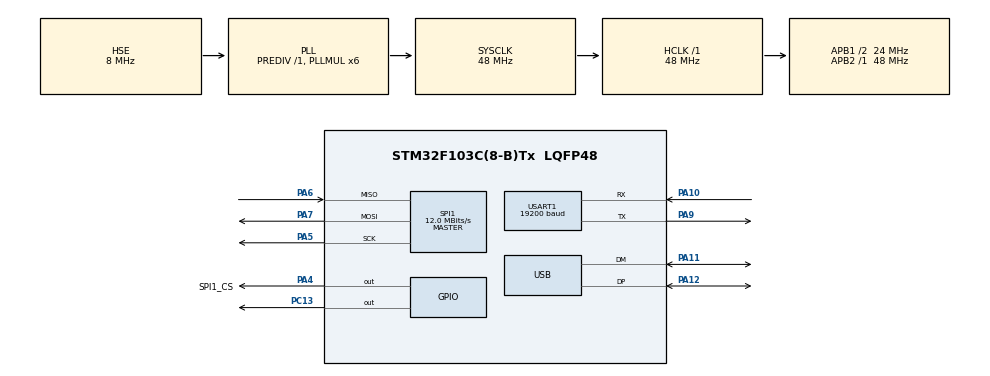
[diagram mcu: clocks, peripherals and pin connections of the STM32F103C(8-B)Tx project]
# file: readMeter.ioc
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Mcu.Family=STM32F1
Mcu.Name=STM32F103C(8-B)Tx
Mcu.Package=LQFP48
NVIC.PriorityGroup=NVIC_PRIORITYGROUP_4
NVIC.RTC_IRQn=true\:0\:0\:false\:false\:true\:true
NVIC.USART1_IRQn=true\:0\:0\:false\:true\:true\:1\:true
NVIC.USB_LP_CAN1_RX0_IRQn=true\:0\:0\:false\:false\:true\:false
PA10.Mode=Asynchronous
PA10.Signal=USART1_RX
PA11.Mode=Device
PA11.Signal=USB_DM
PA12.Mode=Device
PA12.Signal=USB_DP
PA4.GPIO_Label=SPI1_CS
PA4.Signal=GPIO_Output
PA5.Mode=Full_Duplex_Master
PA5.Signal=SPI1_SCK
PA6.Mode=Full_Duplex_Master
PA6.Signal=SPI1_MISO
PA7.Mode=Full_Duplex_Master
PA7.Signal=SPI1_MOSI
PA9.Mode=Asynchronous
PA9.Signal=USART1_TX
PC13-TAMPER-RTC.Signal=GPIO_Output
PC14-OSC32_IN.Mode=LSE-External-Oscillator
PC14-OSC32_IN.Signal=RCC_OSC32_IN
PC15-OSC32_OUT.Mode=LSE-External-Oscillator
PC15-OSC32_OUT.Signal=RCC_OSC32_OUT
PD0-OSC_IN.Mode=HSE-External-Oscillator
PD0-OSC_IN.Signal=RCC_OSC_IN
PD1-OSC_OUT.Mode=HSE-External-Oscillator
PD1-OSC_OUT.Signal=RCC_OSC_OUT
ProjectManager.HeapSize=0x200
ProjectManager.StackSize=0x400
ProjectManager.TargetToolchain=Makefile
RCC.AHBFreq_Value=48000000
RCC.APB1CLKDivider=RCC_HCLK_DIV2
RCC.APB1Freq_Value=24000000
RCC.APB1TimFreq_Value=48000000
RCC.APB2Freq_Value=48000000
RCC.APB2TimFreq_Value=48000000
RCC.HCLKFreq_Value=48000000
RCC.PLLMUL=RCC_PLL_MUL6
RCC.RTCClockSelection=RCC_RTCCLKSOURCE_LSE
RCC.SYSCLKFreq_VALUE=48000000
RCC.SYSCLKSource=RCC_SYSCLKSOURCE_PLLCLK
RCC.USBFreq_Value=48000000
RTC.Format=RTC_FORMAT_BIN
RTC.OutPut=RTC_OUTPUTSOURCE_ALARM
SPI1.BaudRatePrescaler=SPI_BAUDRATEPRESCALER_4
SPI1.CalculateBaudRate=12.0 MBits/s
SPI1.Direction=SPI_DIRECTION_2LINES
SPI1.Mode=SPI_MODE_MASTER
SPI1.VirtualType=VM_MASTER
USART1.BaudRate=19200
USART1.Parity=PARITY_ODD
USART1.VirtualMode=VM_ASYNC
USB_DEVICE.CLASS_NAME_FS=CDC
USB_DEVICE.VirtualMode=Cdc
USB_DEVICE.VirtualModeFS=Cdc_FS
VP_FATFS_VS_Generic.Mode=User_defined
VP_RTC_VS_RTC_Activate.Mode=RTC_Enabled
VP_SYS_VS_ND.Mode=No_Debug
VP_USB_DEVICE_VS_USB_DEVICE_CDC_FS.Mode=CDC_FS
board=readMeter

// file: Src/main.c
/**
  ******************************************************************************
  * @file           : main.c
  * @brief          : Main program body
  ******************************************************************************
  * This notice applies to any and all portions of this file
  * that are not between comment pairs USER CODE BEGIN and
  * USER CODE END. Other portions of this file, whether
  * inserted by the user or by software development tools
  * are owned by their respective copyright owners.
  *
  * Copyright (c) 2018 STMicroelectronics International N.V.
  * All rights reserved.
  *
  * Redistribution and use in source and binary forms, with or without
  * modification, are permitted, provided that the following conditions are met:
  *
  * 1. Redistribution of source code must retain the above copyright notice,
  *    this list of conditions and the following disclaimer.
  * 2. Redistributions in binary form must reproduce the above copyright notice,
  *    this list of conditions and the following disclaimer in the documentation
  *    and/or other materials provided with the distribution.
  * 3. Neither the name of STMicroelectronics nor the names of other
  *    contributors to this software may be used to endorse or promote products
  *    derived from this software without specific written permission.
  * 4. This software, including modifications and/or derivative works of this
  *    software, must execute solely and exclusively on microcontroller or
  *    microprocessor devices manufactured by or for STMicroelectronics.
  * 5. Redistribution and use of this software other than as permitted under
  *    this license is void and will automatically terminate your rights under
  *    this license.
  *
  * THIS SOFTWARE IS PROVIDED BY STMICROELECTRONICS AND CONTRIBUTORS "AS IS"
  * AND ANY EXPRESS, IMPLIED OR STATUTORY WARRANTIES, INCLUDING, BUT NOT
  * LIMITED TO, THE IMPLIED WARRANTIES OF MERCHANTABILITY, FITNESS FOR A
  * PARTICULAR PURPOSE AND NON-INFRINGEMENT OF THIRD PARTY INTELLECTUAL PROPERTY
  * RIGHTS ARE DISCLAIMED TO THE FULLEST EXTENT PERMITTED BY LAW. IN NO EVENT
  * SHALL STMICROELECTRONICS OR CONTRIBUTORS BE LIABLE FOR ANY DIRECT, INDIRECT,
  * INCIDENTAL, SPECIAL, EXEMPLARY, OR CONSEQUENTIAL DAMAGES (INCLUDING, BUT NOT
  * LIMITED TO, PROCUREMENT OF SUBSTITUTE GOODS OR SERVICES; LOSS OF USE, DATA,
  * OR PROFITS; OR BUSINESS INTERRUPTION) HOWEVER CAUSED AND ON ANY THEORY OF
  * LIABILITY, WHETHER IN CONTRACT, STRICT LIABILITY, OR TORT (INCLUDING
  * NEGLIGENCE OR OTHERWISE) ARISING IN ANY WAY OUT OF THE USE OF THIS SOFTWARE,
  * EVEN IF ADVISED OF THE POSSIBILITY OF SUCH DAMAGE.
  *
  ******************************************************************************
  */
#include "main.h"
#include "stm32f1xx_hal.h"
#include "fatfs.h"
#include "rtc.h"
#include "spi.h"
#include "usart.h"
#include "usb_device.h"
#include "gpio.h"

/* USER CODE BEGIN PV */
/* Private variables ---------------------------------------------------------*/

/* USER CODE END PV */

void SystemClock_Config(void);
static void MX_NVIC_Init(void);

/* USER CODE BEGIN PFP */
/* Private function prototypes -----------------------------------------------*/

/* USER CODE END PFP */

int main(void)
{

  /* MCU Configuration----------------------------------------------------------*/

  /* Reset of all peripherals, Initializes the Flash interface and the Systick. */
  HAL_Init();

  /* Configure the system clock */
  SystemClock_Config();

  /* Initialize all configured peripherals */
  MX_GPIO_Init();
  MX_USB_DEVICE_Init();
  MX_USART1_UART_Init();
  MX_SPI1_Init();
  MX_FATFS_Init();
  MX_RTC_Init();

  /* Initialize interrupts */
  MX_NVIC_Init();
  /* USER CODE BEGIN 2 */
  HAL_UART_Receive_IT(&huart1, rxData, 1);
  /* USER CODE END 2 */

  /* Infinite loop */
  while (1)
  {

  /* USER CODE BEGIN 3 */
  //If we have received data
  if (meterDataReady==1){
	//Toggle LED on bluepill
	HAL_GPIO_TogglePin(GPIOC,GPIO_PIN_13);
	//Write data to current file on SD
	fs_WriteFile();
	//Reset meter data
	meterDataReady=0;
  }

  //Check if button is pressed
  if (!HAL_GPIO_ReadPin(GPIOB, GPIO_PIN_0)){
	//Read current file and send data to USB
        readLastFile();
	//Delay a bit
        HAL_Delay(1000);
	//Open new file
        MX_FATFS_Init();
  }

  }
  /* USER CODE END 3 */

}

void SystemClock_Config(void)
{

  RCC_OscInitTypeDef RCC_OscInitStruct;
  RCC_ClkInitTypeDef RCC_ClkInitStruct;
  RCC_PeriphCLKInitTypeDef PeriphClkInit;

    /**Initializes the CPU, AHB and APB busses clocks
    */
  RCC_OscInitStruct.OscillatorType = RCC_OSCILLATORTYPE_HSE|RCC_OSCILLATORTYPE_LSE;
  RCC_OscInitStruct.HSEState = RCC_HSE_ON;
  RCC_OscInitStruct.HSEPredivValue = RCC_HSE_PREDIV_DIV1;
  RCC_OscInitStruct.LSEState = RCC_LSE_ON;
  RCC_OscInitStruct.HSIState = RCC_HSI_ON;
  RCC_OscInitStruct.PLL.PLLState = RCC_PLL_ON;
  RCC_OscInitStruct.PLL.PLLSource = RCC_PLLSOURCE_HSE;
  RCC_OscInitStruct.PLL.PLLMUL = RCC_PLL_MUL6;
  if (HAL_RCC_OscConfig(&RCC_OscInitStruct) != HAL_OK)
  {
    _Error_Handler(__FILE__, __LINE__);
  }

    /**Initializes the CPU, AHB and APB busses clocks
    */
  RCC_ClkInitStruct.ClockType = RCC_CLOCKTYPE_HCLK|RCC_CLOCKTYPE_SYSCLK
                              |RCC_CLOCKTYPE_PCLK1|RCC_CLOCKTYPE_PCLK2;
  RCC_ClkInitStruct.SYSCLKSource = RCC_SYSCLKSOURCE_PLLCLK;
  RCC_ClkInitStruct.AHBCLKDivider = RCC_SYSCLK_DIV1;
  RCC_ClkInitStruct.APB1CLKDivider = RCC_HCLK_DIV2;
  RCC_ClkInitStruct.APB2CLKDivider = RCC_HCLK_DIV1;

  if (HAL_RCC_ClockConfig(&RCC_ClkInitStruct, FLASH_LATENCY_1) != HAL_OK)
  {
    _Error_Handler(__FILE__, __LINE__);
  }

  PeriphClkInit.PeriphClockSelection = RCC_PERIPHCLK_RTC|RCC_PERIPHCLK_USB;
  PeriphClkInit.RTCClockSelection = RCC_RTCCLKSOURCE_LSE;
  PeriphClkInit.UsbClockSelection = RCC_USBCLKSOURCE_PLL;
  if (HAL_RCCEx_PeriphCLKConfig(&PeriphClkInit) != HAL_OK)
  {
    _Error_Handler(__FILE__, __LINE__);
  }

    /**Configure the Systick interrupt time
    */
  HAL_SYSTICK_Config(HAL_RCC_GetHCLKFreq()/1000);

    /**Configure the Systick
    */
  HAL_SYSTICK_CLKSourceConfig(SYSTICK_CLKSOURCE_HCLK);

  /* SysTick_IRQn interrupt configuration */
  HAL_NVIC_SetPriority(SysTick_IRQn, 0, 0);
}

/**
  * @brief NVIC Configuration.
  * @retval None
  */
static void MX_NVIC_Init(void)
{
  /* USART1_IRQn interrupt configuration */
  HAL_NVIC_SetPriority(USART1_IRQn, 0, 0);
  HAL_NVIC_EnableIRQ(USART1_IRQn);
}

void _Error_Handler(char *file, int line)
{
  while(1)
  {
  }
}

/************************ (C) COPYRIGHT STMicroelectronics *****END OF FILE****/
